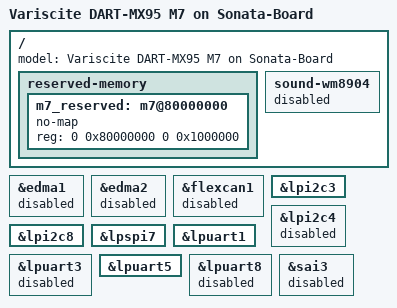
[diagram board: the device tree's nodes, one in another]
// SPDX-License-Identifier: (GPL-2.0+ OR MIT)
/*
 * Copyright 2025 Variscite Ltd.
 */

#include "imx95-var-dart-sonata.dts"

/ {
	model = "Variscite DART-MX95 M7 on Sonata-Board";

	reserved-memory {
		m7_reserved: m7@80000000 {
			no-map;
			reg = <0 0x80000000 0 0x1000000>;
		};
	};

	/* SAI3 requires eDMA2, which is reserved for the Cortex-M7. */
	sound-wm8904 {
		status = "disabled";
	};
};

/* Reserve the peripherals used by the Cortex-M7 firmware. */
&edma1 {
	status = "reserved";
};

&edma2 {
	status = "reserved";
};

&flexcan1 {
	status = "reserved";
};

/* Keep Linux I2C, SPI and UART controllers running in PIO mode. */
&lpi2c3 {
	/delete-property/ dmas;
	/delete-property/ dma-names;
};

&lpi2c4 {
	status = "reserved";
};

&lpi2c8 {
	/delete-property/ dmas;
	/delete-property/ dma-names;
};

&lpspi7 {
	/delete-property/ dmas;
	/delete-property/ dma-names;
};

&lpuart1 {
	/delete-property/ dmas;
	/delete-property/ dma-names;
};

&lpuart3 {
	status = "reserved";
};

&lpuart5 {
	/delete-property/ dmas;
	/delete-property/ dma-names;
};

&lpuart8 {
	status = "reserved";
};

&sai3 {
	status = "disabled";
};
